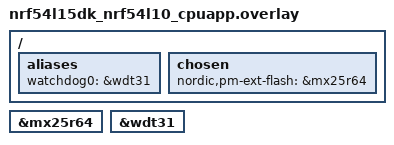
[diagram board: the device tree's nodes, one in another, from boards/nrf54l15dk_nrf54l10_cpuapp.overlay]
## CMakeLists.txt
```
#
# Copyright (c) 2025 Nordic Semiconductor ASA
#
# SPDX-License-Identifier: LicenseRef-Nordic-5-Clause
#

cmake_minimum_required(VERSION 3.20.0)

include(${CMAKE_CURRENT_LIST_DIR}/../../cmake/find_zephyr.cmake)

project(matter-manufacturer_specific)

include(${ZEPHYR_NCS_MATTER_MODULE_DIR}/cmake/zap_helpers.cmake)
ncs_get_zap_parent_dir(ZAP_PARENT_DIR)

# Override zap-generated directory.
get_filename_component(CHIP_APP_ZAP_DIR ${ZAP_PARENT_DIR}/zap-generated REALPATH CACHE)

# NORDIC SDK APP START

include(${ZEPHYR_NCS_MATTER_MODULE_DIR}/cmake/data_model.cmake)

target_include_directories(app PRIVATE
  src
  ${ZAP_PARENT_DIR}
)

target_sources(app PRIVATE
  src/app_task.cpp
  src/zcl_callbacks.cpp
  src/main.cpp
  src/basic_information_extension.cpp
)

ncs_configure_data_model(
  EXTERNAL_CLUSTERS "NORDIC_DEV_KIT_CLUSTER"
)
# NORDIC SDK APP END
```

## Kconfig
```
#
# Copyright (c) 2025 Nordic Semiconductor
#
# SPDX-License-Identifier: LicenseRef-Nordic-5-Clause
#
mainmenu "Matter nRF Connect Manufacturer Specific Example Application"

# Sample configuration used for Thread networking
if OPENTHREAD

choice OPENTHREAD_NORDIC_LIBRARY_CONFIGURATION
	default OPENTHREAD_NORDIC_LIBRARY_MTD
endchoice

choice OPENTHREAD_DEVICE_TYPE
	default OPENTHREAD_MTD
endchoice

choice OPENTHREAD_IMPLEMENTATION
	default OPENTHREAD_SOURCES
endchoice

endif # OPENTHREAD

config CHIP_WIFI
	default y if SHIELD_NRF7002EB2

source "$(ZEPHYR_CONNECTEDHOMEIP_MODULE_DIR)/config/nrfconnect/chip-module/Kconfig.features"
source "$(ZEPHYR_CONNECTEDHOMEIP_MODULE_DIR)/config/nrfconnect/chip-module/Kconfig.defaults"
source "Kconfig.zephyr"
```

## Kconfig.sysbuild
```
#
# Copyright (c) 2025 Nordic Semiconductor ASA
#
# SPDX-License-Identifier: LicenseRef-Nordic-5-Clause
#

#### Radio core selection
config NRF_DEFAULT_IPC_RADIO
	default y

# Enable IEEE802.15.4 serialization to network core
# This config automatically pulls in the `overlay-802154.conf` in the ipc_radio image
config NETCORE_IPC_RADIO_IEEE802154
	default y if SOC_SERIES_NRF53 && !WIFI_NRF70

# Enable Bluetooth serialization to network core
# This config automatically pulls in the `overlay-bt_hci_ipc.conf` in the ipc_radio image
config NETCORE_IPC_RADIO_BT_HCI_IPC
	default y if (SOC_SERIES_NRF53 || SOC_SERIES_NRF54H)

#### Bootloader
choice BOOTLOADER
	default BOOTLOADER_MCUBOOT if !BOARD_NATIVE_SIM
endchoice

if BOOTLOADER_MCUBOOT

#### DFU multi-image support
config DFU_MULTI_IMAGE_PACKAGE_BUILD
	default y

config DFU_MULTI_IMAGE_PACKAGE_APP
	default y

#### DFU network core configuration
if SOC_SERIES_NRF53

choice MCUBOOT_MODE
	default MCUBOOT_MODE_OVERWRITE_ONLY
endchoice

choice BOOT_SIGNATURE_TYPE
	default BOOT_SIGNATURE_TYPE_RSA
endchoice

config SECURE_BOOT_NETCORE
	default y

config NETCORE_APP_UPDATE
	default y

config DFU_MULTI_IMAGE_PACKAGE_NET
	default y

endif # SOC_SERIES_NRF53
endif # BOOTLOADER_MCUBOOT

#### Enable generating factory data
config MATTER_ADD_ON_FACTORY_DATA_GENERATE
	default y if !BOARD_NATIVE_SIM

source "$(ZEPHYR_BASE)/share/sysbuild/Kconfig"
```

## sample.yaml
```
sample:
  description: Matter Manufacturer Specific sample
  name: Matter Manufacturer Specific
common:
  tags:
    - sysbuild
    - ci_samples_matter
tests:
  sample.matter.manufacturer_specific.debug:
    sysbuild: true
    build_only: true
    integration_platforms:
      - nrf5340dk/nrf5340/cpuapp
      - nrf54l15dk/nrf54l15/cpuapp
      - nrf54l15dk/nrf54l10/cpuapp
      - nrf54lm20dk/nrf54lm20b/cpuapp
      - nrf54lm20dk/nrf54lm20a/cpuapp
    platform_allow:
      - nrf5340dk/nrf5340/cpuapp
      - nrf54l15dk/nrf54l15/cpuapp
      - nrf54l15dk/nrf54l10/cpuapp
      - nrf54lm20dk/nrf54lm20b/cpuapp
      - nrf54lm20dk/nrf54lm20a/cpuapp
  sample.matter.manufacturer_specific.tfm:
    sysbuild: true
    build_only: true
    extra_args:
      - FILE_SUFFIX=tfm
    integration_platforms:
      - nrf54l15dk/nrf54l15/cpuapp/ns
    platform_allow:
      - nrf54l15dk/nrf54l15/cpuapp/ns
  sample.matter.manufacturer_specific.nrf7002eb2.debug:
    sysbuild: true
    build_only: true
    extra_args:
      - manufacturer_specific_SHIELD=nrf7002eb2
      - SB_CONFIG_WIFI_NRF70=y
    integration_platforms:
      - nrf54lm20dk/nrf54lm20b/cpuapp
      - nrf54lm20dk/nrf54lm20a/cpuapp
    platform_allow:
      - nrf54lm20dk/nrf54lm20b/cpuapp
      - nrf54lm20dk/nrf54lm20a/cpuapp
```

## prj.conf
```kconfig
#
# Copyright (c) 2025 Nordic Semiconductor ASA
#
# SPDX-License-Identifier: LicenseRef-Nordic-5-Clause
#

# This sample uses Kconfig.defaults to set options common for all
# samples. This file should contain only options specific for this sample
# or overrides of default values.

# Enable CHIP
CONFIG_CHIP=y
CONFIG_CHIP_PROJECT_CONFIG="src/chip_project_config.h"
CONFIG_CHIP_DEVICE_PRODUCT_NAME="Matter Manufacturer Specific"

# Configure ZAP file name
CONFIG_MATTER_ZAP_FILE_PATH="${APPLICATION_CONFIG_DIR}/src/default_zap/manufacturer_specific.zap"
CONFIG_CHIP_APP_ZAP_DIR="${APPLICATION_CONFIG_DIR}/src/default_zap/zap-generated"

# 32768 == 0x8000 (example Product ID added temporaly,
# but it must be changed with proper PID from the list:
# https://github.com/project-chip/connectedhomeip/blob/482e6fd03196a6de45465a90003947ef4b86e0b1/docs/examples/discussion/PID_allocation_for_example_apps.md)
CONFIG_CHIP_DEVICE_PRODUCT_ID=32768
CONFIG_STD_CPP17=y

# Increase system workqueue stack size
CONFIG_SYSTEM_WORKQUEUE_STACK_SIZE=2048

# Enable Matter pairing automatically on application start.
CONFIG_CHIP_ENABLE_PAIRING_AUTOSTART=y

# Enable Matter extended announcement and increase duration to 1 hour.
CONFIG_CHIP_BLE_EXT_ADVERTISING=y
CONFIG_CHIP_BLE_ADVERTISING_DURATION=60

# Add support for LEDs and buttons on Nordic development kits
CONFIG_DK_LIBRARY=y

# Bluetooth Low Energy configuration
CONFIG_BT_DEVICE_NAME="MatterMS"

# Other settings
CONFIG_THREAD_NAME=y
CONFIG_MPU_STACK_GUARD=y
CONFIG_RESET_ON_FATAL_ERROR=n
CONFIG_CHIP_LIB_SHELL=y
CONFIG_MATTER_TEST_SHELL=y

# Disable NFC onboarding
CONFIG_CHIP_NFC_ONBOARDING_PAYLOAD=n

# Reduce application size
CONFIG_USE_SEGGER_RTT=n

# Enable Factory Data feature
CONFIG_CHIP_FACTORY_DATA=y
CONFIG_CHIP_FACTORY_DATA_BUILD=y

# For manufacturer specific samples, the ZAP file must be statically generated
CONFIG_MATTER_ZAP_GENERATION_STATIC=y
```

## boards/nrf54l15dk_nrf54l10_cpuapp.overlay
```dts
/*
 * Copyright (c) 2025 Nordic Semiconductor ASA
 *
 * SPDX-License-Identifier: LicenseRef-Nordic-5-Clause
 */

#include <nrf54l10_cpuapp_partitions.dtsi>

/ {
	aliases {
		/* Use watchdog wdt31 as the application watchdog */
		watchdog0 = &wdt31;
	};

	chosen {
		nordic,pm-ext-flash = &mx25r64;
	};
};

&mx25r64 {
	status = "okay";
};

&wdt31 {
	status = "okay";
};
```

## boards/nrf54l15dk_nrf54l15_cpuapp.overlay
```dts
/*
 * Copyright (c) 2025 Nordic Semiconductor ASA
 *
 * SPDX-License-Identifier: LicenseRef-Nordic-5-Clause
 */

#include <nrf54l15_cpuapp_partitions.dtsi>

/ {
	aliases {
		/* Use watchdog wdt31 as the application watchdog */
		watchdog0 = &wdt31;
	};

	chosen {
		nordic,pm-ext-flash = &mx25r64;
	};
};

&mx25r64 {
	status = "okay";
};

&wdt31 {
	status = "okay";
};
```

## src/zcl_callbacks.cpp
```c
/*
 * Copyright (c) 2025 Nordic Semiconductor ASA
 *
 * SPDX-License-Identifier: LicenseRef-Nordic-5-Clause
 */

#include <lib/support/logging/CHIPLogging.h>

#include "app_task.h"
#include "board/board.h"

#include <app-common/zap-generated/attributes/Accessors.h>
#include <app-common/zap-generated/callback.h>
#include <app/ConcreteAttributePath.h>
#include <zap-generated/PluginApplicationCallbacks.h>

using namespace ::chip;
using namespace ::chip::app;
using namespace ::chip::app::Clusters;
using namespace ::chip::app::Clusters::NordicDevKit::Commands;
using namespace ::chip::app::Clusters::BasicInformation::Commands;

bool emberAfNordicDevKitClusterSetLEDCallback(CommandHandler *commandObj, const ConcreteCommandPath &commandPath,
					      const SetLED::DecodableType &commandData)
{
	switch (commandData.action) {
	case NordicDevKit::LEDActionEnum::kOff:
		Nrf::GetBoard().GetLED(Nrf::DeviceLeds::LED2).Set(false);
		break;
	case NordicDevKit::LEDActionEnum::kOn:
		Nrf::GetBoard().GetLED(Nrf::DeviceLeds::LED2).Set(true);
		break;
	case NordicDevKit::LEDActionEnum::kToggle:
		Nrf::GetBoard().GetLED(Nrf::DeviceLeds::LED2).Invert();
		break;
	default:
		commandObj->AddStatus(commandPath, Protocols::InteractionModel::Status::Failure);
		return true;
	}

	AppTask::Instance().UpdateNordicDevkitClusterState();
	commandObj->AddStatus(commandPath, Protocols::InteractionModel::Status::Success);

	return true;
}

void MatterNordicDevKitPluginServerInitCallback()
{
	/* Intentionally empty */
}

void MatterPostAttributeChangeCallback(const ConcreteAttributePath &attributePath, uint8_t type, uint16_t size,
				       uint8_t *value)
{
	/* Intentionally empty */
}

/** @brief NordicDevkit Cluster Init
 *
 * This function is called when a specific cluster is initialized. It gives the
 * application an opportunity to take care of cluster initialization procedures.
 * It is called exactly once for each endpoint where cluster is present.
 *
 * @param endpoint   Ver.: always
 *
 */
void emberAfNordicDevKitClusterInitCallback(EndpointId endpoint)
{
	Protocols::InteractionModel::Status status;
	bool storedValue;

	/* Read storedValue UserLED value */
	status = NordicDevKit::Attributes::UserLED::Get(endpoint, &storedValue);
	if (status == Protocols::InteractionModel::Status::Success) {
		/* Set actual state to the cluster state that was last persisted */
		Nrf::GetBoard().GetLED(Nrf::DeviceLeds::LED2).Set(storedValue);
	}
}

/** @brief Basic Information Cluster Init
 *
 * This function is called when a specific cluster is initialized. It gives the
 * application an opportunity to take care of cluster initialization procedures.
 * It is called exactly once for each endpoint where cluster is present.
 *
 * @param endpoint   Ver.: always
 *
 */
void emberAfBasicInformationClusterInitCallback(EndpointId /* unused */)
{
	AppTask::Instance().UpdateBasicInformationClusterState();
}
```
